AUTOSAR XML (schema 00050)
package /ComponentTypes
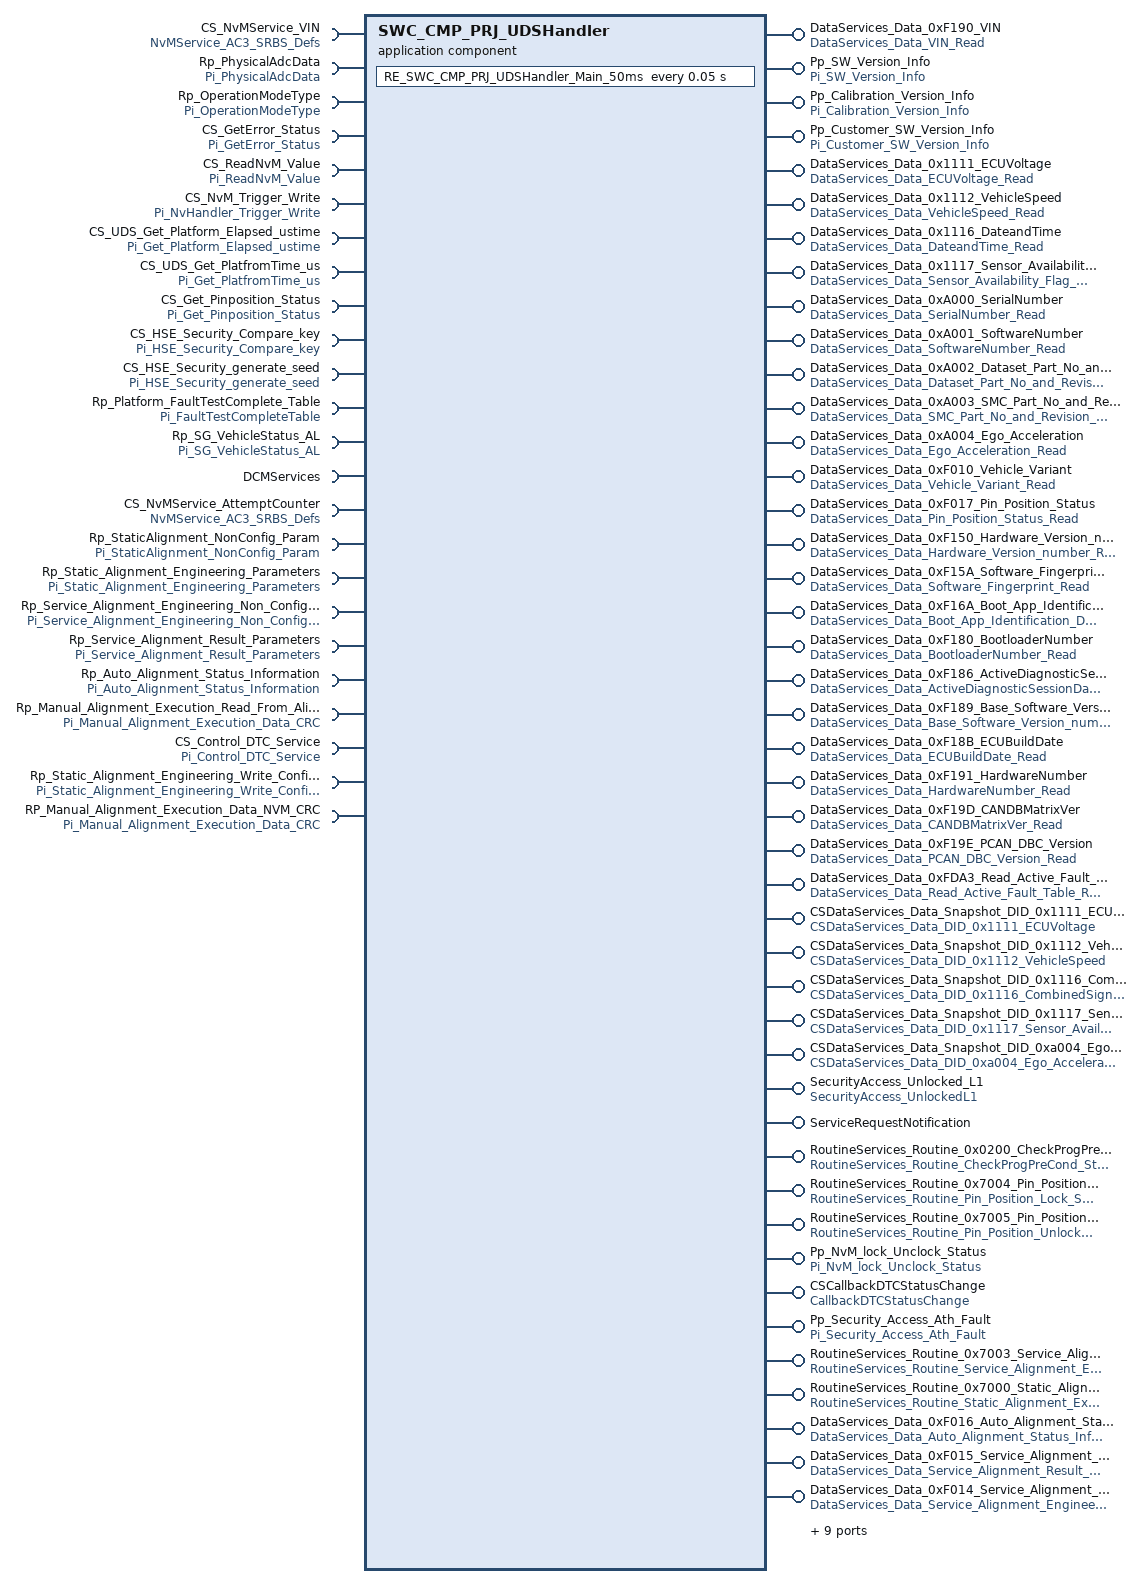
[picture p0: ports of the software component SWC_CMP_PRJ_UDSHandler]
  application sw component type SWC_CMP_PRJ_UDSHandler
    provide port DataServices_Data_0xF190_VIN: provided-interface=DataServices_Data_VIN_Read
      provided-com-specs:
        operation=WriteData, queue-length=1
        operation=ConditionCheckRead, queue-length=1
        operation=ReadData, queue-length=1
    require port CS_NvMService_VIN: required-com-specs=[EraseBlock, InvalidateNvBlock, RestoreBlockDefaults, WriteBlock, ReadBlock, SetRamBlockStatus, GetErrorStatus], required-interface=NvMService_AC3_SRBS_Defs
    25 x provide port:
      Pp_SW_Version_Info: nonqueued-sender-com-spec{data-element=De_SW_Version_Info, init-value=fields=[SwReleaseRevision:0, SwMajorRevision:0, SwMinorRevision:0, SwFieldRevision:0, DbcMajorRevision:0, DbcMinorRevision:0, FBLMajorRevision:0, FBLMinorRevision:0, FBLPromoteRevision:0, BMMajorRevision:0, BMMinorRevision:0, BMFieldRevision:0, ASRMajorRevision:0, ASRMinorRevision:0, ASRfieldRevision:0]}, provided-interface=Pi_SW_Version_Info
      Pp_Calibration_Version_Info: nonqueued-sender-com-spec{data-element=De_Calibration_Version_Info, init-value=fields=[SMC_MajorVersion:0, SMC_PlatformRevision:0, SMC_Compatablity:0, USC_MajorVersion:0, USC_PlatformRevision:0, USC_Compatablity:0, Julian_Year:0, Julian_Date:0]}, provided-interface=Pi_Calibration_Version_Info
      Pp_Customer_SW_Version_Info: nonqueued-sender-com-spec{data-element=De_Customer_SW_Version_Info, init-value=fields=[{short-label=Customer_SW_Version, fields=[Major_Version:0, Minor_Version:0, Patch_Version:0]}, {short-label=Customer_BL_Version, fields=[Major_Version:0, Minor_Version:0, Patch_Version:0]}, {short-label=Customer_BM_Version, fields=[Major_Version:0, Minor_Version:0, Patch_Version:0]}]}, provided-interface=Pi_Customer_SW_Version_Info
      DataServices_Data_0x1111_ECUVoltage: provided-com-specs=[{operation=ConditionCheckRead, queue-length=1}, {operation=ReadData, queue-length=1}], provided-interface=DataServices_Data_ECUVoltage_Read
      DataServices_Data_0x1112_VehicleSpeed: provided-com-specs=[{operation=ConditionCheckRead, queue-length=1}, {operation=ReadData, queue-length=1}], provided-interface=DataServices_Data_VehicleSpeed_Read
      DataServices_Data_0x1116_DateandTime: provided-com-specs=[{operation=ConditionCheckRead, queue-length=1}, {operation=ReadData, queue-length=1}], provided-interface=DataServices_Data_DateandTime_Read
      DataServices_Data_0x1117_Sensor_Availability_Flag: provided-com-specs=[{operation=ConditionCheckRead, queue-length=1}, {operation=ReadData, queue-length=1}], provided-interface=DataServices_Data_Sensor_Availability_Flag_Read
      DataServices_Data_0xA000_SerialNumber: provided-com-specs=[{operation=ConditionCheckRead, queue-length=1}, {operation=ReadData, queue-length=1}], provided-interface=DataServices_Data_SerialNumber_Read
      DataServices_Data_0xA001_SoftwareNumber: provided-com-specs=[{operation=ConditionCheckRead, queue-length=1}, {operation=ReadData, queue-length=1}], provided-interface=DataServices_Data_SoftwareNumber_Read
      DataServices_Data_0xA002_Dataset_Part_No_and_Revision: provided-com-specs=[{operation=ConditionCheckRead, queue-length=1}, {operation=ReadData, queue-length=1}], provided-interface=DataServices_Data_Dataset_Part_No_and_Revision_Read
      DataServices_Data_0xA003_SMC_Part_No_and_Revision: provided-com-specs=[{operation=ConditionCheckRead, queue-length=1}, {operation=ReadData, queue-length=1}], provided-interface=DataServices_Data_SMC_Part_No_and_Revision_Read
      DataServices_Data_0xA004_Ego_Acceleration: provided-com-specs=[{operation=ConditionCheckRead, queue-length=1}, {operation=ReadData, queue-length=1}], provided-interface=DataServices_Data_Ego_Acceleration_Read
      DataServices_Data_0xF010_Vehicle_Variant: provided-com-specs=[{operation=ConditionCheckRead, queue-length=1}, {operation=ReadData, queue-length=1}], provided-interface=DataServices_Data_Vehicle_Variant_Read
      DataServices_Data_0xF017_Pin_Position_Status: provided-com-specs=[{operation=ConditionCheckRead, queue-length=1}, {operation=ReadData, queue-length=1}], provided-interface=DataServices_Data_Pin_Position_Status_Read
      DataServices_Data_0xF150_Hardware_Version_number: provided-com-specs=[{operation=ConditionCheckRead, queue-length=1}, {operation=ReadData, queue-length=1}], provided-interface=DataServices_Data_Hardware_Version_number_Read
      DataServices_Data_0xF15A_Software_Fingerprint: provided-interface=DataServices_Data_Software_Fingerprint_Read
        provided-com-specs:
          operation=WriteData, queue-length=1
          operation=ConditionCheckRead, queue-length=1
          operation=ReadData, queue-length=1
      DataServices_Data_0xF16A_Boot_App_Identification: provided-com-specs=[{operation=ConditionCheckRead, queue-length=1}, {operation=ReadData, queue-length=1}], provided-interface=DataServices_Data_Boot_App_Identification_DID_Read
      DataServices_Data_0xF180_BootloaderNumber: provided-com-specs=[{operation=ConditionCheckRead, queue-length=1}, {operation=ReadData, queue-length=1}], provided-interface=DataServices_Data_BootloaderNumber_Read
      DataServices_Data_0xF186_ActiveDiagnosticSessionDataIdentifier: provided-com-specs=[{operation=ConditionCheckRead, queue-length=1}, {operation=ReadData, queue-length=1}], provided-interface=DataServices_Data_ActiveDiagnosticSessionDataIdentifier_Read
      DataServices_Data_0xF189_Base_Software_Version_number: provided-com-specs=[{operation=ConditionCheckRead, queue-length=1}, {operation=ReadData, queue-length=1}], provided-interface=DataServices_Data_Base_Software_Version_number_Read
      DataServices_Data_0xF18B_ECUBuildDate: provided-com-specs=[{operation=ConditionCheckRead, queue-length=1}, {operation=ReadData, queue-length=1}], provided-interface=DataServices_Data_ECUBuildDate_Read
      DataServices_Data_0xF191_HardwareNumber: provided-com-specs=[{operation=ConditionCheckRead, queue-length=1}, {operation=ReadData, queue-length=1}], provided-interface=DataServices_Data_HardwareNumber_Read
      DataServices_Data_0xF19D_CANDBMatrixVer: provided-com-specs=[{operation=ConditionCheckRead, queue-length=1}, {operation=ReadData, queue-length=1}], provided-interface=DataServices_Data_CANDBMatrixVer_Read
      DataServices_Data_0xF19E_PCAN_DBC_Version: provided-com-specs=[{operation=ConditionCheckRead, queue-length=1}, {operation=ReadData, queue-length=1}], provided-interface=DataServices_Data_PCAN_DBC_Version_Read
      DataServices_Data_0xFDA3_Read_Active_Fault_Table: provided-com-specs=[{operation=ConditionCheckRead, queue-length=1}, {operation=ReadData, queue-length=1}], provided-interface=DataServices_Data_Read_Active_Fault_Table_Read
    require port Rp_PhysicalAdcData: nonqueued-receiver-com-spec{data-element=De_PhysicalAdcData, filter=data-filter-type=ALWAYS, init-value=fields=[Adc_Board_Rev:0, Adc_Batt_Volt:0, Adc_Pos_Gnd_A:0, Adc_Pos_Gnd_B:0, Adc_Pos_Gnd_C:0, Adc_Pos_Gnd_D:0, Adc_Eth_0v9:0, Adc_Rdi_Detect:0, Adc_MMIC_Temp:0, Adc_Mcu_Temp:0, Validity_Flag:0]}, required-interface=Pi_PhysicalAdcData
    require port Rp_OperationModeType: nonqueued-receiver-com-spec{data-element=De_OperationMode_System, filter=data-filter-type=ALWAYS, init-value=0}, required-interface=Pi_OperationModeType
    10 x provide port:
      CSDataServices_Data_Snapshot_DID_0x1111_ECUVoltage: server-com-spec{operation=ReadData, queue-length=1}, provided-interface=CSDataServices_Data_DID_0x1111_ECUVoltage
      CSDataServices_Data_Snapshot_DID_0x1112_VehicleSpeed: server-com-spec{operation=ReadData, queue-length=1}, provided-interface=CSDataServices_Data_DID_0x1112_VehicleSpeed
      CSDataServices_Data_Snapshot_DID_0x1116_CombinedSignal: server-com-spec{operation=ReadData, queue-length=1}, provided-interface=CSDataServices_Data_DID_0x1116_CombinedSignal
      CSDataServices_Data_Snapshot_DID_0x1117_Sensor_Availability_Flag_Information: server-com-spec{operation=ReadData, queue-length=1}, provided-interface=CSDataServices_Data_DID_0x1117_Sensor_Availability_Flag_Information
      CSDataServices_Data_Snapshot_DID_0xa004_Ego_Acceleration: server-com-spec{operation=ReadData, queue-length=1}, provided-interface=CSDataServices_Data_DID_0xa004_Ego_Acceleration
      SecurityAccess_Unlocked_L1: provided-interface=SecurityAccess_UnlockedL1
        provided-com-specs:
          operation=CompareKey, queue-length=1
          operation=GetSeed, queue-length=1
          operation=SetSecurityAttemptCounter, queue-length=1
          operation=GetSecurityAttemptCounter, queue-length=1
      ServiceRequestNotification: provided-com-specs=[{operation=Confirmation, queue-length=1}, {operation=Indication, queue-length=1}], provided-interface=ServiceRequestNotification
      RoutineServices_Routine_0x0200_CheckProgPreCond_Start: server-com-spec{operation=Start, queue-length=1}, provided-interface=RoutineServices_Routine_CheckProgPreCond_Start
      RoutineServices_Routine_0x7004_Pin_Position_Lock_Start: provided-com-specs=[{operation=RequestResults, queue-length=1}, {operation=Start, queue-length=1}], provided-interface=RoutineServices_Routine_Pin_Position_Lock_Start
      RoutineServices_Routine_0x7005_Pin_Position_Unlock_Start: provided-com-specs=[{operation=RequestResults, queue-length=1}, {operation=Start, queue-length=1}], provided-interface=RoutineServices_Routine_Pin_Position_Unlock_Start
    require port CS_GetError_Status: client-com-spec=Operation, required-interface=Pi_GetError_Status
    require port CS_ReadNvM_Value: client-com-spec=Operation, required-interface=Pi_ReadNvM_Value
    require port CS_NvM_Trigger_Write: client-com-spec=NvHandler_Trigger_Write_To_NVM, required-interface=Pi_NvHandler_Trigger_Write
    provide port Pp_NvM_lock_Unclock_Status: nonqueued-sender-com-spec{data-element=De_NvM_lock_Unclock_Status, init-value=constant-reference=C_SensorPos_default}, provided-interface=Pi_NvM_lock_Unclock_Status
    provide port CSCallbackDTCStatusChange: server-com-spec{operation=DTCStatusChanged, queue-length=1}, provided-interface=CallbackDTCStatusChange
    provide port Pp_Security_Access_Ath_Fault: nonqueued-sender-com-spec{data-element=De_Security_Access_Ath_Fault, init-value=170}, provided-interface=Pi_Security_Access_Ath_Fault
    8 x require port:
      CS_UDS_Get_Platform_Elapsed_ustime: client-com-spec=read, required-interface=Pi_Get_Platform_Elapsed_ustime
      CS_UDS_Get_PlatfromTime_us: client-com-spec=read, required-interface=Pi_Get_PlatfromTime_us
      CS_Get_Pinposition_Status: client-com-spec=Operation, required-interface=Pi_Get_Pinposition_Status
      CS_HSE_Security_Compare_key: client-com-spec=Operation, required-interface=Pi_HSE_Security_Compare_key
      CS_HSE_Security_generate_seed: client-com-spec=Operation, required-interface=Pi_HSE_Security_generate_seed
      Rp_Platform_FaultTestComplete_Table: nonqueued-receiver-com-spec{data-element=De_FaultTestCompleteTable, filter=data-filter-type=ALWAYS, init-value=constant-reference=C_Fault_T}, required-interface=Pi_FaultTestCompleteTable
      Rp_SG_VehicleStatus_AL: nonqueued-receiver-com-spec{data-element=Vdp_SG_VehicleStatus_AL, filter=data-filter-type=ALWAYS, init-value=fields=[SSTS_CAN_PCAN_MAJOR_ADAS:0, SSTS_CAN_PCAN_MINOR_ADAS:0, SSTS_DRIVE_DIR:0, SSTS_DRIVE_REVERSE:0, SSTS_GEAR_POSITION:0, SSTS_IGN_STATUS:0, SSTS_MH_VS_CRC16:0, SSTS_MH_VS_CYCLE_COUNTER:0, SSTS_STEERING_ANGLE:0, SSTS_STEERING_ANGLE_SIGN:0, SSTS_SW_VERSION_ADAS:0, SSTS_VEH_AbsoluteTime_Day:0, SSTS_VEH_AbsoluteTime_Hour:0, SSTS_VEH_AbsoluteTime_Minute:0, SSTS_VEH_AbsoluteTime_Month:0, SSTS_VEH_AbsoluteTime_Second:0, SSTS_VEH_AbsoluteTime_Year:0, SSTS_VEH_ODOMETER:0, SSTS_VEH_POWER_MODE_STATUS:0, SSTS_VEH_SPD_COMP_FACTOR:0, SSTS_VEH_Status_CMAC:5 x 0, SSTS_VEH_Status_FV:7 x 0, SSTS_VEH_SYSTEM_VOLTAGE:0, SSTS_VEH_TRAILER_CONNECTED:0, SSTS_VEH_VARIANT:0, SSTS_VEHICLE_SPEED_CALC:0, SSTS_VEHICLE_SPEED_CALC_QF:0, SSTS_VEHICLE_STATE:0, SSTS_VIN_Data_Byte0:0, SSTS_VIN_Data_Byte1:0, SSTS_VIN_Data_Byte2:0, SSTS_VIN_Data_Byte3:0, SSTS_VIN_Data_Byte4:0, SSTS_VIN_Data_Byte5:0, SSTS_VIN_Data_Byte6:0, SSTS_VIN_FrameIdx:0, SSTS_YAW_RATE_BIAS:0, SSTS_YAW_RATE_CALC:0, SSTS_YAW_RATE_CALC_QF:0]}, required-interface=Pi_SG_VehicleStatus_AL
      DCMServices: required-interface=DCMServices
        required-com-specs:
          GetRequestKind
          SetActiveDiagnostic
          GetSecurityLevel
          ResetToDefaultSession
          GetSesCtrlType
          GetActiveProtocol
    10 x provide port:
      RoutineServices_Routine_0x7003_Service_Alignment_Execution_Start: provided-interface=RoutineServices_Routine_Service_Alignment_Execution_Start
        provided-com-specs:
          operation=RequestResults, queue-length=1
          operation=Stop, queue-length=1
          operation=Start, queue-length=1
      RoutineServices_Routine_0x7000_Static_Alignment_Execution_Start: provided-interface=RoutineServices_Routine_Static_Alignment_Execution_Start
        provided-com-specs:
          operation=RequestResults, queue-length=1
          operation=Stop, queue-length=1
          operation=Start, queue-length=1
      DataServices_Data_0xF016_Auto_Alignment_Status_Information: provided-com-specs=[{operation=ConditionCheckRead, queue-length=1}, {operation=ReadData, queue-length=1}], provided-interface=DataServices_Data_Auto_Alignment_Status_Information_Read
      DataServices_Data_0xF015_Service_Alignment_Result_Parameters: provided-com-specs=[{operation=ConditionCheckRead, queue-length=1}, {operation=ReadData, queue-length=1}], provided-interface=DataServices_Data_Service_Alignment_Result_Parameters_Read
      DataServices_Data_0xF014_Service_Alignment_Engineering_Non_Configuration_Parameters: provided-com-specs=[{operation=ConditionCheckRead, queue-length=1}, {operation=ReadData, queue-length=1}], provided-interface=DataServices_Data_Service_Alignment_Engineering_Non_Configuration_Parameters_Read
      DataServices_Data_0xF013_Static_Alignment_Engineering_Write_Configuration_Parameter: server-com-spec{operation=WriteData, queue-length=1}, provided-interface=DataServices_Data_Static_Alignment_Engineering_Write_Configuration_Parameter_Write
      DataServices_Data_0xF012_Static_Alignment_Engineering_Read_Parameters: provided-com-specs=[{operation=ConditionCheckRead, queue-length=1}, {operation=ReadData, queue-length=1}], provided-interface=DataServices_Data_Static_Alignment_Engineering_Read_Parameters_Read
      DataServices_Data_0xF011_Static_Alignment_Engineering_Non_Configuration_Parameters: provided-com-specs=[{operation=ConditionCheckRead, queue-length=1}, {operation=ReadData, queue-length=1}], provided-interface=DataServices_Data_Static_Alignment_Engineering_Non_Configuration_Parameters_Read
      DataServices_Data_0xF01C_Static_Alignment_Result_Parameters: provided-com-specs=[{operation=ConditionCheckRead, queue-length=1}, {operation=ReadData, queue-length=1}], provided-interface=DataServices_Data_Static_Alignment_Result_Parameters_Read
      DataServices_Data_0xF01B_Manual_Alignment_Execution: provided-interface=DataServices_Data_Manual_Alignment_Execution_Read
        provided-com-specs:
          operation=WriteData, queue-length=1
          operation=ConditionCheckRead, queue-length=1
          operation=ReadData, queue-length=1
    require port CS_NvMService_AttemptCounter: required-com-specs=[WriteBlock, SetRamBlockStatus, RestoreBlockDefaults, ReadBlock, InvalidateNvBlock, GetErrorStatus, EraseBlock], required-interface=NvMService_AC3_SRBS_Defs
    require port Rp_StaticAlignment_NonConfig_Param: nonqueued-receiver-com-spec{data-element=De_DID_StaticAlignment_NonConfig_Param_T, filter=data-filter-type=ALWAYS, init-value=fields=[AlignmentStatic_NumberOfScans:0, AlignmentStatic_RangeOffset_Threshold:0, RangeRateUpper_Threshold:0, RCS_Min:0, RCS_Max:0, Velocity_Max:0, Yaw_Max:0, FlatPlateWidth_Lower_Limit:0, FlatPlateWidth_Upper_Limit:0, FlatPlateHeight_Lower_Limit:0, FlatPlateHeight_Upper_Limit:0, FlatPlateRCS_Lower_Limit:0, FlatPlateRCS_Upper_Limit:0, FlatPlateRange_Lower_Limit:0, FlatPlateRange_Upper_Limit:0, FlatPlateAzimuth_Lower_Limit:0, FlatPlateAzimuth_Upper_Limit:0, FlatPlateElevation_Lower_Limit:0, FlatPlateElevation_Upper_Limit:0, FlatPlateRangeRate_Lower_Limit:0, FlatPlateRangeRate_Upper_Limit:0]}, required-interface=Pi_StaticAlignment_NonConfig_Param
    require port Rp_Static_Alignment_Engineering_Parameters: nonqueued-receiver-com-spec{data-element=De_Static_Alignment_Engineering_Parameters, filter=data-filter-type=ALWAYS, init-value=fields=[AlignmentStatic_AzimuthUpper_Threshold:0, AlignmentStatic_AzimuthLower_Threshold:0, AlignmentStatic_ElevationUpper_Threshold:0, AlignmentStatic_ElevationLower_Threshold:0, AlignmentStatic_TargetAzimuth:0, AlignmentStatic_TargetElevation:0, AlignmentStatic_TargetDistance:0]}, required-interface=Pi_Static_Alignment_Engineering_Parameters
    provide port Pp_Static_Alignment_Engineering_Write_Configuration_Parameters_CRC: nonqueued-sender-com-spec{data-element=De_Static_Alignment_Engineering_Write_Configuration_Parameters_CRC, init-value=fields=[{short-label=Static_alignment_write_Params, fields=[AlignmentStatic_TargetAzimuth:0, AlignmentStatic_TargetElevation:0, AlignmentStatic_TargetDistance:120]}, Data_CRC:0]}, provided-interface=Pi_Static_Alignment_Engineering_Write_Configuration_Parameters_CRC
    4 x require port:
      Rp_Service_Alignment_Engineering_Non_Configuration_Parameters: nonqueued-receiver-com-spec{data-element=De_Service_Alignment_Engineering_Non_Configuration_Parameters, filter=data-filter-type=ALWAYS, init-value=fields=[AlignService_Abs_Dist_Th:0, AlignService_Eff_Dist_Th:0, AlignService_Abs_Duration_Th:0, AlignService_Eff_Duration_Th:0, AlignService_Vel_Min:0, AlignService_Vel_Max:0, AlignService_Yawrate_Max:0]}, required-interface=Pi_Service_Alignment_Engineering_Non_Configuration_Parameters
      Rp_Service_Alignment_Result_Parameters: nonqueued-receiver-com-spec{data-element=De_Service_Alignment_Result_Parameters, filter=data-filter-type=ALWAYS, init-value=fields=[AlignmentModeOut:0, AlignmentServiceStatus:0, AlignmentError:0, AlignmentAzimuth:0, AlignmentElevation:0, AlignmentRoll:0, AzimuthStd:0, ElevationStd:0, RollStd:0, CalTime:0, ProgressPercent:0, CalDisplay:0, 0, 0, 0, 0, VehicleCondition:0, AverageNumberOfDetections:0, AverageSpeed:0, DistanceAbsolute:0, DistanceEffective:0, DurationAbsolute:0, DurationEffective:0, 0, 0, 0, 0]}, required-interface=Pi_Service_Alignment_Result_Parameters
      Rp_Auto_Alignment_Status_Information: nonqueued-receiver-com-spec{data-element=De_Auto_Alignment_Status_Information, filter=data-filter-type=ALWAYS, init-value=fields=[AlignmentModeOut:0, AlignmentAutoStatus:0, AutoAlignmentFailRootCause:0, StartAzimuth:0, StartElevation:0, StartRoll:0, AACurrentAzimuth:0, AACurrentElevation:0, AACurrentRoll:0, AAAzimuthStd:0, AAElevationStd:0, AARollStd:0, 0, 0, 0, 0, AzimuthError_positive:0, ElevationError_positive:0, RollError_positive:0, AzimuthError_negative:0, ElevationError_negative:0, RollError_negative:0, HostSpeedCompensationFactor:0, HostSpeedCompensationFactor_QF:0, AzimuthUpdates:0, ElevationUpdates:0, RollUpdates:0]}, required-interface=Pi_Auto_Alignment_Status_Information
      Rp_Manual_Alignment_Execution_Read_From_Alignment_Data_CRC: nonqueued-receiver-com-spec{data-element=De_Manual_Alignment_Execution_Data_CRC, filter=data-filter-type=ALWAYS, init-value=fields=[{short-label=Manual_Alignment_Execution_Data, fields=[AlignmentModeIn:0, 0, IntialMisalignmentAngleAzimuth:0, IntialMisalignmentAngleElevation:0]}, Data_CRC:0]}, required-interface=Pi_Manual_Alignment_Execution_Data_CRC
    provide port Pp_Manual_Alignment_Execution_Data_From_UDS_CRC: nonqueued-sender-com-spec{data-element=De_Manual_Alignment_Execution_Data_CRC, init-value=fields=[{short-label=Manual_Alignment_Execution_Data, fields=[AlignmentModeIn:0, 0, IntialMisalignmentAngleAzimuth:0, IntialMisalignmentAngleElevation:0]}, Data_CRC:0]}, provided-interface=Pi_Manual_Alignment_Execution_Data_CRC
    require port CS_Control_DTC_Service: client-com-spec=Operation, required-interface=Pi_Control_DTC_Service
    provide port Pp_Static_Alignment_Engineering_Write_Configuration_Parameters_NVM_CRC: nonqueued-sender-com-spec{data-element=De_Static_Alignment_Engineering_Write_Configuration_Parameters_CRC, init-value=fields=[{short-label=Static_alignment_write_Params, fields=[AlignmentStatic_TargetAzimuth:0, AlignmentStatic_TargetElevation:0, AlignmentStatic_TargetDistance:0]}, Data_CRC:0]}, provided-interface=Pi_Static_Alignment_Engineering_Write_Configuration_Parameters_CRC
    require port Rp_Static_Alignment_Engineering_Write_Configuration_Parameters_NVM_CRC: nonqueued-receiver-com-spec{data-element=De_Static_Alignment_Engineering_Write_Configuration_Parameters_CRC, filter=data-filter-type=ALWAYS, init-value=fields=[{short-label=Static_alignment_write_Params, fields=[AlignmentStatic_TargetAzimuth:0, AlignmentStatic_TargetElevation:0, AlignmentStatic_TargetDistance:0]}, Data_CRC:0]}, required-interface=Pi_Static_Alignment_Engineering_Write_Configuration_Parameters_CRC
    provide port Pp_Manual_Alignment_Execution_Data_NVM_CRC: nonqueued-sender-com-spec{data-element=De_Manual_Alignment_Execution_Data_CRC, init-value=fields=[{short-label=Manual_Alignment_Execution_Data, fields=[AlignmentModeIn:0, 0, IntialMisalignmentAngleAzimuth:0, IntialMisalignmentAngleElevation:0]}, Data_CRC:0]}, provided-interface=Pi_Manual_Alignment_Execution_Data_CRC
    require port RP_Manual_Alignment_Execution_Data_NVM_CRC: nonqueued-receiver-com-spec{data-element=De_Manual_Alignment_Execution_Data_CRC, filter=data-filter-type=ALWAYS, init-value=fields=[{short-label=Manual_Alignment_Execution_Data, fields=[AlignmentModeIn:0, 0, IntialMisalignmentAngleAzimuth:0, IntialMisalignmentAngleElevation:0]}, Data_CRC:0]}, required-interface=Pi_Manual_Alignment_Execution_Data_CRC
    behavior SWC_CMP_PRJ_UDSHandler_InternalBehavior: data-type-mapping=[DataTypeMappings_DEV, defaultDataTypeMappingSet_CPFS], handle-termination-and-restart=NO-SUPPORT
      ar-typed-per-instance-memorys:
        data SWC_UDS_VIN: sw-calibration-access=READ-ONLY, type=Dt_VIN_T, init-value=constant-reference=C_VIN_T
        data SWC_UDS_AttemptCounter: sw-calibration-access=READ-ONLY, type=AttempCounter_Type, init-value=fields=[AttemptCounter1:0, AttemptCounter2:0]
      operation invoked event OIT_DataServices_Data_0xF190_VIN_WriteData_DataServices_Data_0xF190_VIN_WriteData: start-on-event=DataServices_Data_0xF190_VIN_WriteData, operation=DataServices_Data_0xF190_VIN.WriteData
      operation invoked event OIT_DataServices_Data_0xF190_VIN_ConditionCheckRead_DataServices_Data_0xF190_VIN_ConditionCheckRead: start-on-event=DataServices_Data_0xF190_VIN_ConditionCheckRead, operation=DataServices_Data_0xF190_VIN.ConditionCheckRead
      operation invoked event OIT_DataServices_Data_0xF190_VIN_ReadData_DataServices_Data_0xF190_VIN_ReadData: start-on-event=DataServices_Data_0xF190_VIN_ReadData, operation=DataServices_Data_0xF190_VIN.ReadData
      timing event TMT_RE_SWC_CMP_PRJ_UDSHandler_Main_50ms: start-on-event=RE_SWC_CMP_PRJ_UDSHandler_Main_50ms, period=0.05
      84 x operation invoked event:
        OIT_DataServices_Data_0x1111_ECUVoltage_ConditionCheckRead_DataServices_Data_0x1111_ECUVoltage_ConditionCheckRead: start-on-event=DataServices_Data_0x1111_ECUVoltage_ConditionCheckRead, operation=DataServices_Data_0x1111_ECUVoltage.ConditionCheckRead
        OIT_DataServices_Data_0x1111_ECUVoltage_ReadData_DataServices_Data_0x1111_ECUVoltage_ReadData: start-on-event=DataServices_Data_0x1111_ECUVoltage_ReadData, operation=DataServices_Data_0x1111_ECUVoltage.ReadData
        OIT_DataServices_Data_0x1112_VehicleSpeed_ConditionCheckRead_DataServices_Data_0x1112_VehicleSpeed_ConditionCheckRead: start-on-event=DataServices_Data_0x1112_VehicleSpeed_ConditionCheckRead, operation=DataServices_Data_0x1112_VehicleSpeed.ConditionCheckRead
        OIT_DataServices_Data_0x1112_VehicleSpeed_ReadData_DataServices_Data_0x1112_VehicleSpeed_ReadData: start-on-event=DataServices_Data_0x1112_VehicleSpeed_ReadData, operation=DataServices_Data_0x1112_VehicleSpeed.ReadData
        OIT_DataServices_Data_0x1116_DateandTime_ConditionCheckRead_DataServices_Data_0x1116_DateandTime_ConditionCheckRead: start-on-event=DataServices_Data_0x1116_DateandTime_ConditionCheckRead, operation=DataServices_Data_0x1116_DateandTime.ConditionCheckRead
        OIT_DataServices_Data_0x1116_DateandTime_ReadData_DataServices_Data_0x1116_DateandTime_ReadData: start-on-event=DataServices_Data_0x1116_DateandTime_ReadData, operation=DataServices_Data_0x1116_DateandTime.ReadData
        OIT_DataServices_Data_0x1117_Sensor_Availability_Flag_ConditionCheckRead_DataServices_Data_0x1117_Sensor_Availability_FlC3AC68A5: start-on-event=DataServices_Data_0x1117_Sensor_Availability_Flag_ConditionCheckRead, operation=DataServices_Data_0x1117_Sensor_Availability_Flag.ConditionCheckRead
        OIT_DataServices_Data_0x1117_Sensor_Availability_Flag_ReadData_DataServices_Data_0x1117_Sensor_Availability_Flag_ReadData: start-on-event=DataServices_Data_0x1117_Sensor_Availability_Flag_ReadData, operation=DataServices_Data_0x1117_Sensor_Availability_Flag.ReadData
        OIT_DataServices_Data_0xA000_SerialNumber_ConditionCheckRead_DataServices_Data_0xA000_SerialNumber_ConditionCheckRead: start-on-event=DataServices_Data_0xA000_SerialNumber_ConditionCheckRead, operation=DataServices_Data_0xA000_SerialNumber.ConditionCheckRead
        OIT_DataServices_Data_0xA000_SerialNumber_ReadData_DataServices_Data_0xA000_SerialNumber_ReadData: start-on-event=DataServices_Data_0xA000_SerialNumber_ReadData, operation=DataServices_Data_0xA000_SerialNumber.ReadData
        OIT_DataServices_Data_0xA001_SoftwareNumber_ConditionCheckRead_DataServices_Data_0xA001_SoftwareNumber_ConditionCheckRead: start-on-event=DataServices_Data_0xA001_SoftwareNumber_ConditionCheckRead, operation=DataServices_Data_0xA001_SoftwareNumber.ConditionCheckRead
        OIT_DataServices_Data_0xA001_SoftwareNumber_ReadData_DataServices_Data_0xA001_SoftwareNumber_ReadData: start-on-event=DataServices_Data_0xA001_SoftwareNumber_ReadData, operation=DataServices_Data_0xA001_SoftwareNumber.ReadData
        OIT_DataServices_Data_0xA002_Dataset_Part_No_and_Revision_ConditionCheckRead_DataServices_Data_0xA002_Dataset_Part_No_an2C00C244: start-on-event=DataServices_Data_0xA002_Dataset_Part_No_and_Revision_ConditionCheckRead, operation=DataServices_Data_0xA002_Dataset_Part_No_and_Revision.ConditionCheckRead
        OIT_DataServices_Data_0xA002_Dataset_Part_No_and_Revision_ReadData_DataServices_Data_0xA002_Dataset_Part_No_and_Revision58D1EF9A: start-on-event=DataServices_Data_0xA002_Dataset_Part_No_and_Revision_ReadData, operation=DataServices_Data_0xA002_Dataset_Part_No_and_Revision.ReadData
        OIT_DataServices_Data_0xA003_SMC_Part_No_and_Revision_ConditionCheckRead_DataServices_Data_0xA003_SMC_Part_No_and_Revisi4479C802: start-on-event=DataServices_Data_0xA003_SMC_Part_No_and_Revision_ConditionCheckRead, operation=DataServices_Data_0xA003_SMC_Part_No_and_Revision.ConditionCheckRead
        OIT_DataServices_Data_0xA003_SMC_Part_No_and_Revision_ReadData_DataServices_Data_0xA003_SMC_Part_No_and_Revision_ReadData: start-on-event=DataServices_Data_0xA003_SMC_Part_No_and_Revision_ReadData, operation=DataServices_Data_0xA003_SMC_Part_No_and_Revision.ReadData
        OIT_DataServices_Data_0xA004_Ego_Acceleration_ConditionCheckRead_DataServices_Data_0xA004_Ego_Acceleration_ConditionCheckRead: start-on-event=DataServices_Data_0xA004_Ego_Acceleration_ConditionCheckRead, operation=DataServices_Data_0xA004_Ego_Acceleration.ConditionCheckRead
        OIT_DataServices_Data_0xA004_Ego_Acceleration_ReadData_DataServices_Data_0xA004_Ego_Acceleration_ReadData: start-on-event=DataServices_Data_0xA004_Ego_Acceleration_ReadData, operation=DataServices_Data_0xA004_Ego_Acceleration.ReadData
        OIT_DataServices_Data_0xF010_Vehicle_Variant_ConditionCheckRead_DataServices_Data_0xF010_Vehicle_Variant_ConditionCheckRead: start-on-event=DataServices_Data_0xF010_Vehicle_Variant_ConditionCheckRead, operation=DataServices_Data_0xF010_Vehicle_Variant.ConditionCheckRead
        OIT_DataServices_Data_0xF010_Vehicle_Variant_ReadData_DataServices_Data_0xF010_Vehicle_Variant_ReadData: start-on-event=DataServices_Data_0xF010_Vehicle_Variant_ReadData, operation=DataServices_Data_0xF010_Vehicle_Variant.ReadData
        OIT_DataServices_Data_0xF017_Pin_Position_Status_ConditionCheckRead_DataServices_Data_0xF017_Pin_Position_Status_Conditi46601389: start-on-event=DataServices_Data_0xF017_Pin_Position_Status_ConditionCheckRead, operation=DataServices_Data_0xF017_Pin_Position_Status.ConditionCheckRead
        OIT_DataServices_Data_0xF017_Pin_Position_Status_ReadData_DataServices_Data_0xF017_Pin_Position_Status_ReadData: start-on-event=DataServices_Data_0xF017_Pin_Position_Status_ReadData, operation=DataServices_Data_0xF017_Pin_Position_Status.ReadData
        OIT_DataServices_Data_0xF150_Hardware_Version_number_ConditionCheckRead_DataServices_Data_0xF150_Hardware_Version_number5319F0E0: start-on-event=DataServices_Data_0xF150_Hardware_Version_number_ConditionCheckRead, operation=DataServices_Data_0xF150_Hardware_Version_number.ConditionCheckRead
        OIT_DataServices_Data_0xF150_Hardware_Version_number_ReadData_DataServices_Data_0xF150_Hardware_Version_number_ReadData: start-on-event=DataServices_Data_0xF150_Hardware_Version_number_ReadData, operation=DataServices_Data_0xF150_Hardware_Version_number.ReadData
        OIT_DataServices_Data_0xF15A_Software_Fingerprint_WriteData_DataServices_Data_0xF15A_Software_Fingerprint_WriteData: start-on-event=DataServices_Data_0xF15A_Software_Fingerprint_WriteData, operation=DataServices_Data_0xF15A_Software_Fingerprint.WriteData
        OIT_DataServices_Data_0xF15A_Software_Fingerprint_ConditionCheckRead_DataServices_Data_0xF15A_Software_Fingerprint_Condi6D559378: start-on-event=DataServices_Data_0xF15A_Software_Fingerprint_ConditionCheckRead, operation=DataServices_Data_0xF15A_Software_Fingerprint.ConditionCheckRead
        OIT_DataServices_Data_0xF15A_Software_Fingerprint_ReadData_DataServices_Data_0xF15A_Software_Fingerprint_ReadData: start-on-event=DataServices_Data_0xF15A_Software_Fingerprint_ReadData, operation=DataServices_Data_0xF15A_Software_Fingerprint.ReadData
        OIT_DataServices_Data_0xF16A_Boot_App_Identification_ConditionCheckRead_DataServices_Data_0xF16A_Boot_App_Identification9C41B615: start-on-event=DataServices_Data_0xF16A_Boot_App_Identification_ConditionCheckRead, operation=DataServices_Data_0xF16A_Boot_App_Identification.ConditionCheckRead
        OIT_DataServices_Data_0xF16A_Boot_App_Identification_ReadData_DataServices_Data_0xF16A_Boot_App_Identification_ReadData: start-on-event=DataServices_Data_0xF16A_Boot_App_Identification_ReadData, operation=DataServices_Data_0xF16A_Boot_App_Identification.ReadData
        OIT_DataServices_Data_0xF180_BootloaderNumber_ConditionCheckRead_DataServices_Data_0xF180_BootloaderNumber_ConditionCheckRead: start-on-event=DataServices_Data_0xF180_BootloaderNumber_ConditionCheckRead, operation=DataServices_Data_0xF180_BootloaderNumber.ConditionCheckRead
        OIT_DataServices_Data_0xF180_BootloaderNumber_ReadData_DataServices_Data_0xF180_BootloaderNumber_ReadData: start-on-event=DataServices_Data_0xF180_BootloaderNumber_ReadData, operation=DataServices_Data_0xF180_BootloaderNumber.ReadData
        OIT_DataServices_Data_0xF186_ActiveDiagnosticSessionDataIdentifier_ConditionCheckRead_DataServices_Data_0xF186_ActiveDia76F3A2B5: start-on-event=DataServices_Data_0xF186_ActiveDiagnosticSessionDataIdentifier_ConditionCheckRead, operation=DataServices_Data_0xF186_ActiveDiagnosticSessionDataIdentifier.ConditionCheckRead
        OIT_DataServices_Data_0xF186_ActiveDiagnosticSessionDataIdentifier_ReadData_DataServices_Data_0xF186_ActiveDiagnosticSes4023728F: start-on-event=DataServices_Data_0xF186_ActiveDiagnosticSessionDataIdentifier_ReadData, operation=DataServices_Data_0xF186_ActiveDiagnosticSessionDataIdentifier.ReadData
        OIT_DataServices_Data_0xF189_Base_Software_Version_number_ConditionCheckRead_DataServices_Data_0xF189_Base_Software_Vers7E0CB6E2: start-on-event=DataServices_Data_0xF189_Base_Software_Version_number_ConditionCheckRead, operation=DataServices_Data_0xF189_Base_Software_Version_number.ConditionCheckRead
        OIT_DataServices_Data_0xF189_Base_Software_Version_number_ReadData_DataServices_Data_0xF189_Base_Software_Version_number3E358C8D: start-on-event=DataServices_Data_0xF189_Base_Software_Version_number_ReadData, operation=DataServices_Data_0xF189_Base_Software_Version_number.ReadData
        OIT_DataServices_Data_0xF18B_ECUBuildDate_ConditionCheckRead_DataServices_Data_0xF18B_ECUBuildDate_ConditionCheckRead: start-on-event=DataServices_Data_0xF18B_ECUBuildDate_ConditionCheckRead, operation=DataServices_Data_0xF18B_ECUBuildDate.ConditionCheckRead
        OIT_DataServices_Data_0xF18B_ECUBuildDate_ReadData_DataServices_Data_0xF18B_ECUBuildDate_ReadData: start-on-event=DataServices_Data_0xF18B_ECUBuildDate_ReadData, operation=DataServices_Data_0xF18B_ECUBuildDate.ReadData
        OIT_DataServices_Data_0xF191_HardwareNumber_ConditionCheckRead_DataServices_Data_0xF191_HardwareNumber_ConditionCheckRead: start-on-event=DataServices_Data_0xF191_HardwareNumber_ConditionCheckRead, operation=DataServices_Data_0xF191_HardwareNumber.ConditionCheckRead
        OIT_DataServices_Data_0xF191_HardwareNumber_ReadData_DataServices_Data_0xF191_HardwareNumber_ReadData: start-on-event=DataServices_Data_0xF191_HardwareNumber_ReadData, operation=DataServices_Data_0xF191_HardwareNumber.ReadData
        OIT_DataServices_Data_0xF19D_CANDBMatrixVer_ConditionCheckRead_DataServices_Data_0xF19D_CANDBMatrixVer_ConditionCheckRead: start-on-event=DataServices_Data_0xF19D_CANDBMatrixVer_ConditionCheckRead, operation=DataServices_Data_0xF19D_CANDBMatrixVer.ConditionCheckRead
        OIT_DataServices_Data_0xF19D_CANDBMatrixVer_ReadData_DataServices_Data_0xF19D_CANDBMatrixVer_ReadData: start-on-event=DataServices_Data_0xF19D_CANDBMatrixVer_ReadData, operation=DataServices_Data_0xF19D_CANDBMatrixVer.ReadData
        OIT_DataServices_Data_0xF19E_PCAN_DBC_Version_ConditionCheckRead_DataServices_Data_0xF19E_PCAN_DBC_Version_ConditionCheckRead: start-on-event=DataServices_Data_0xF19E_PCAN_DBC_Version_ConditionCheckRead, operation=DataServices_Data_0xF19E_PCAN_DBC_Version.ConditionCheckRead
        OIT_DataServices_Data_0xF19E_PCAN_DBC_Version_ReadData_DataServices_Data_0xF19E_PCAN_DBC_Version_ReadData: start-on-event=DataServices_Data_0xF19E_PCAN_DBC_Version_ReadData, operation=DataServices_Data_0xF19E_PCAN_DBC_Version.ReadData
        OIT_CSDataServices_Data_Snapshot_DID_0x1111_ECUVoltage_ReadData_CSDataServices_Data_Snapshot_DID_0x1111_ECUVoltage_ReadData: start-on-event=CSDataServices_Data_Snapshot_DID_0x1111_ECUVoltage_ReadData, operation=CSDataServices_Data_Snapshot_DID_0x1111_ECUVoltage.ReadData
        OIT_CSDataServices_Data_Snapshot_DID_0x1117_Sensor_Availability_Flag_Information_ReadData_CSDataServices_Data_Snapshot_DDAA3099C: start-on-event=CSDataServices_Data_Snapshot_DID_0x1117_Sensor_Availability_Flag_Information_ReadData, operation=CSDataServices_Data_Snapshot_DID_0x1117_Sensor_Availability_Flag_Information.ReadData
        OIT_CSDataServices_Data_Snapshot_DID_0xa004_Ego_Acceleration_ReadData_CSDataServices_Data_Snapshot_DID_0xa004_Ego_AcceleA5E32AA8: start-on-event=CSDataServices_Data_Snapshot_DID_0xa004_Ego_Acceleration_ReadData, operation=CSDataServices_Data_Snapshot_DID_0xa004_Ego_Acceleration.ReadData
        OIT_CSDataServices_Data_Snapshot_DID_0x1112_VehicleSpeed_ReadData_CSDataServices_Data_Snapshot_DID_0x1112_VehicleSpeed_ReadData: start-on-event=CSDataServices_Data_Snapshot_DID_0x1112_VehicleSpeed_ReadData, operation=CSDataServices_Data_Snapshot_DID_0x1112_VehicleSpeed.ReadData
        OIT_CSDataServices_Data_Snapshot_DID_0x1116_CombinedSignal_ReadData_CSDataServices_Data_Snapshot_DID_0x1116_CombinedSignA3433445: start-on-event=CSDataServices_Data_Snapshot_DID_0x1116_CombinedSignal_ReadData, operation=CSDataServices_Data_Snapshot_DID_0x1116_CombinedSignal.ReadData
        OIT_ServiceRequestNotification_Confirmation_ServiceRequestNotification_Confirmation: start-on-event=ServiceRequestNotification_Confirmation, operation=ServiceRequestNotification.Confirmation
        OIT_ServiceRequestNotification_Indication_ServiceRequestNotification_Indication: start-on-event=ServiceRequestNotification_Indication, operation=ServiceRequestNotification.Indication
        OIT_RoutineServices_Routine_0x7005_Pin_Position_Unlock_Start_RequestResults_RoutineServices_Routine_0x7005_Pin_Position_DA16A899: start-on-event=RoutineServices_Routine_0x7005_Pin_Position_Unlock_Start_RequestResults, operation=RoutineServices_Routine_0x7005_Pin_Position_Unlock_Start.RequestResults
        OIT_RoutineServices_Routine_0x7005_Pin_Position_Unlock_Start_Start_RoutineServices_Routine_0x7005_Pin_Position_Unlock_St48C89B13: start-on-event=RoutineServices_Routine_0x7005_Pin_Position_Unlock_Start_Start, operation=RoutineServices_Routine_0x7005_Pin_Position_Unlock_Start.Start
        OIT_RoutineServices_Routine_0x0200_CheckProgPreCond_Start_Start_RoutineServices_Routine_0x0200_CheckProgPreCond_Start_Start: start-on-event=RoutineServices_Routine_0x0200_CheckProgPreCond_Start_Start, operation=RoutineServices_Routine_0x0200_CheckProgPreCond_Start.Start
        OIT_RoutineServices_Routine_0x7004_Pin_Position_Lock_Start_RequestResults_RoutineServices_Routine_0x7004_Pin_Position_Lo83125386: start-on-event=RoutineServices_Routine_0x7004_Pin_Position_Lock_Start_RequestResults, operation=RoutineServices_Routine_0x7004_Pin_Position_Lock_Start.RequestResults
        OIT_RoutineServices_Routine_0x7004_Pin_Position_Lock_Start_Start_RoutineServices_Routine_0x7004_Pin_Position_Lock_Start_Start: start-on-event=RoutineServices_Routine_0x7004_Pin_Position_Lock_Start_Start, operation=RoutineServices_Routine_0x7004_Pin_Position_Lock_Start.Start
        OIT_DataServices_Data_0xFDA3_Read_Active_Fault_Table_ConditionCheckRead_DataServices_Data_0xFDA3_Read_Active_Fault_Table8976C99A: start-on-event=DataServices_Data_0xFDA3_Read_Active_Fault_Table_ConditionCheckRead, operation=DataServices_Data_0xFDA3_Read_Active_Fault_Table.ConditionCheckRead
        OIT_DataServices_Data_0xFDA3_Read_Active_Fault_Table_ReadData_DataServices_Data_0xFDA3_Read_Active_Fault_Table_ReadData: start-on-event=DataServices_Data_0xFDA3_Read_Active_Fault_Table_ReadData, operation=DataServices_Data_0xFDA3_Read_Active_Fault_Table.ReadData
        OIT_CSCallbackDTCStatusChange_DTCStatusChanged_CSCallbackDTCStatusChange_DTCStatusChanged: start-on-event=CSCallbackDTCStatusChange_DTCStatusChanged, operation=CSCallbackDTCStatusChange.DTCStatusChanged
        OIT_SecurityAccess_Unlocked_L1_SetSecurityAttemptCounter_SecurityAccess_Unlocked_L1_SetSecurityAttemptCounter: start-on-event=SecurityAccess_Unlocked_L1_SetSecurityAttemptCounter, operation=SecurityAccess_Unlocked_L1.SetSecurityAttemptCounter
        OIT_SecurityAccess_Unlocked_L1_GetSecurityAttemptCounter_SecurityAccess_Unlocked_L1_GetSecurityAttemptCounter: start-on-event=SecurityAccess_Unlocked_L1_GetSecurityAttemptCounter, operation=SecurityAccess_Unlocked_L1.GetSecurityAttemptCounter
        OIT_SecurityAccess_Unlocked_L1_CompareKey_SecurityAccess_Unlocked_L1_CompareKey: start-on-event=SecurityAccess_Unlocked_L1_CompareKey, operation=SecurityAccess_Unlocked_L1.CompareKey
        OIT_SecurityAccess_Unlocked_L1_GetSeed_SecurityAccess_Unlocked_L1_GetSeed: start-on-event=SecurityAccess_Unlocked_L1_GetSeed, operation=SecurityAccess_Unlocked_L1.GetSeed
        OIT_DataServices_Data_0xF01C_Static_Alignment_Result_Parameters_ConditionCheckRead_DataServices_Data_0xF01C_Static_AlignD8019410: start-on-event=DataServices_Data_0xF01C_Static_Alignment_Result_Parameters_ConditionCheckRead, operation=DataServices_Data_0xF01C_Static_Alignment_Result_Parameters.ConditionCheckRead
        OIT_DataServices_Data_0xF01C_Static_Alignment_Result_Parameters_ReadData_DataServices_Data_0xF01C_Static_Alignment_Resul9B0D7DB7: start-on-event=DataServices_Data_0xF01C_Static_Alignment_Result_Parameters_ReadData, operation=DataServices_Data_0xF01C_Static_Alignment_Result_Parameters.ReadData
        OIT_DataServices_Data_0xF011_Static_Alignment_Engineering_Non_Configuration_Parameters_ConditionCheckRead_DataServices_DCF75DAD5: start-on-event=DataServices_Data_0xF011_Static_Alignment_Engineering_Non_Configuration_Parameters_ConditionCheckRead, operation=DataServices_Data_0xF011_Static_Alignment_Engineering_Non_Configuration_Parameters.ConditionCheckRead
        OIT_DataServices_Data_0xF011_Static_Alignment_Engineering_Non_Configuration_Parameters_ReadData_DataServices_Data_0xF0114E070977: start-on-event=DataServices_Data_0xF011_Static_Alignment_Engineering_Non_Configuration_Parameters_ReadData, operation=DataServices_Data_0xF011_Static_Alignment_Engineering_Non_Configuration_Parameters.ReadData
        OIT_RoutineServices_Routine_0x7003_Service_Alignment_Execution_Start_RequestResults_RoutineServices_Routine_0x7003_ServiA1346617: start-on-event=RoutineServices_Routine_0x7003_Service_Alignment_Execution_Start_RequestResults, operation=RoutineServices_Routine_0x7003_Service_Alignment_Execution_Start.RequestResults
        OIT_RoutineServices_Routine_0x7003_Service_Alignment_Execution_Start_Stop_RoutineServices_Routine_0x7003_Service_Alignme44A434DD: start-on-event=RoutineServices_Routine_0x7003_Service_Alignment_Execution_Start_Stop, operation=RoutineServices_Routine_0x7003_Service_Alignment_Execution_Start.Stop
        OIT_RoutineServices_Routine_0x7003_Service_Alignment_Execution_Start_Start_RoutineServices_Routine_0x7003_Service_Alignm60FF78D2: start-on-event=RoutineServices_Routine_0x7003_Service_Alignment_Execution_Start_Start, operation=RoutineServices_Routine_0x7003_Service_Alignment_Execution_Start.Start
        OIT_RoutineServices_Routine_0x7000_Static_Alignment_Execution_Start_RequestResults_RoutineServices_Routine_0x7000_StaticC951749F: start-on-event=RoutineServices_Routine_0x7000_Static_Alignment_Execution_Start_RequestResults, operation=RoutineServices_Routine_0x7000_Static_Alignment_Execution_Start.RequestResults
        OIT_RoutineServices_Routine_0x7000_Static_Alignment_Execution_Start_Stop_RoutineServices_Routine_0x7000_Static_Alignment6EF74555: start-on-event=RoutineServices_Routine_0x7000_Static_Alignment_Execution_Start_Stop, operation=RoutineServices_Routine_0x7000_Static_Alignment_Execution_Start.Stop
        OIT_RoutineServices_Routine_0x7000_Static_Alignment_Execution_Start_Start_RoutineServices_Routine_0x7000_Static_Alignmen1031943F: start-on-event=RoutineServices_Routine_0x7000_Static_Alignment_Execution_Start_Start, operation=RoutineServices_Routine_0x7000_Static_Alignment_Execution_Start.Start
        OIT_DataServices_Data_0xF016_Auto_Alignment_Status_Information_ConditionCheckRead_DataServices_Data_0xF016_Auto_AlignmenC54767F7: start-on-event=DataServices_Data_0xF016_Auto_Alignment_Status_Information_ConditionCheckRead, operation=DataServices_Data_0xF016_Auto_Alignment_Status_Information.ConditionCheckRead
        OIT_DataServices_Data_0xF016_Auto_Alignment_Status_Information_ReadData_DataServices_Data_0xF016_Auto_Alignment_Status_IE39C6DE0: start-on-event=DataServices_Data_0xF016_Auto_Alignment_Status_Information_ReadData, operation=DataServices_Data_0xF016_Auto_Alignment_Status_Information.ReadData
        OIT_DataServices_Data_0xF015_Service_Alignment_Result_Parameters_ConditionCheckRead_DataServices_Data_0xF015_Service_Ali520B7E9E: start-on-event=DataServices_Data_0xF015_Service_Alignment_Result_Parameters_ConditionCheckRead, operation=DataServices_Data_0xF015_Service_Alignment_Result_Parameters.ConditionCheckRead
        OIT_DataServices_Data_0xF015_Service_Alignment_Result_Parameters_ReadData_DataServices_Data_0xF015_Service_Alignment_ResBCFFEA9C: start-on-event=DataServices_Data_0xF015_Service_Alignment_Result_Parameters_ReadData, operation=DataServices_Data_0xF015_Service_Alignment_Result_Parameters.ReadData
        OIT_DataServices_Data_0xF014_Service_Alignment_Engineering_Non_Configuration_Parameters_ConditionCheckRead_DataServices_4EC705AA: start-on-event=DataServices_Data_0xF014_Service_Alignment_Engineering_Non_Configuration_Parameters_ConditionCheckRead, operation=DataServices_Data_0xF014_Service_Alignment_Engineering_Non_Configuration_Parameters.ConditionCheckRead
        OIT_DataServices_Data_0xF014_Service_Alignment_Engineering_Non_Configuration_Parameters_ReadData_DataServices_Data_0xF01E7B35011: start-on-event=DataServices_Data_0xF014_Service_Alignment_Engineering_Non_Configuration_Parameters_ReadData, operation=DataServices_Data_0xF014_Service_Alignment_Engineering_Non_Configuration_Parameters.ReadData
        OIT_DataServices_Data_0xF01B_Manual_Alignment_Execution_WriteData_DataServices_Data_0xF01B_Manual_Alignment_Execution_WriteData: start-on-event=DataServices_Data_0xF01B_Manual_Alignment_Execution_WriteData, operation=DataServices_Data_0xF01B_Manual_Alignment_Execution.WriteData
        OIT_DataServices_Data_0xF01B_Manual_Alignment_Execution_ConditionCheckRead_DataServices_Data_0xF01B_Manual_Alignment_Exe4C1CC3E0: start-on-event=DataServices_Data_0xF01B_Manual_Alignment_Execution_ConditionCheckRead, operation=DataServices_Data_0xF01B_Manual_Alignment_Execution.ConditionCheckRead
        OIT_DataServices_Data_0xF01B_Manual_Alignment_Execution_ReadData_DataServices_Data_0xF01B_Manual_Alignment_Execution_ReadData: start-on-event=DataServices_Data_0xF01B_Manual_Alignment_Execution_ReadData, operation=DataServices_Data_0xF01B_Manual_Alignment_Execution.ReadData
        OIT_DataServices_Data_0xF012_Static_Alignment_Engineering_Read_Parameters_ConditionCheckRead_DataServices_Data_0xF012_St600605D7: start-on-event=DataServices_Data_0xF012_Static_Alignment_Engineering_Read_Parameters_ConditionCheckRead, operation=DataServices_Data_0xF012_Static_Alignment_Engineering_Read_Parameters.ConditionCheckRead
        OIT_DataServices_Data_0xF012_Static_Alignment_Engineering_Read_Parameters_ReadData_DataServices_Data_0xF012_Static_Align735FEBE5: start-on-event=DataServices_Data_0xF012_Static_Alignment_Engineering_Read_Parameters_ReadData, operation=DataServices_Data_0xF012_Static_Alignment_Engineering_Read_Parameters.ReadData
        OIT_DataServices_Data_0xF013_Static_Alignment_Engineering_Write_Configuration_Parameter_WriteData_DataServices_Data_0xF0635C6EC6: start-on-event=DataServices_Data_0xF013_Static_Alignment_Engineering_Write_Configuration_Parameter_WriteData, operation=DataServices_Data_0xF013_Static_Alignment_Engineering_Write_Configuration_Parameter.WriteData
      per-instance-parameters:
        parameter data prototype SWC_UDSHandler_VIN_DefaultValue: sw-calibration-access=READ-WRITE, type=Dt_VIN_T, init-value=constant-reference=C_VIN_T
      88 x runnable:
        DataServices_Data_0xF190_VIN_WriteData
          sync call SC_CS_NvMService_VIN_GetErrorStatus: operation=CS_NvMService_VIN.GetErrorStatus
          sync call SC_CS_NvMService_VIN_WriteBlock: operation=CS_NvMService_VIN.WriteBlock
        DataServices_Data_0xF190_VIN_ConditionCheckRead
        DataServices_Data_0xF190_VIN_ReadData
          sync call SC_CS_NvMService_VIN_ReadBlock: operation=CS_NvMService_VIN.ReadBlock
        RE_SWC_CMP_PRJ_UDSHandler_Main_50ms
          data-receive-point-by-arguments:
            4 x access:
              REC_Rp_PhysicalAdcData_De_PhysicalAdcData: accessed-variable=Rp_PhysicalAdcData.De_PhysicalAdcData
              REC_Rp_OperationModeType_De_OperationMode_System: accessed-variable=Rp_OperationModeType.De_OperationMode_System
              REC_Rp_Platform_FaultTestComplete_Table_De_FaultTestCompleteTable: accessed-variable=Rp_Platform_FaultTestComplete_Table.De_FaultTestCompleteTable
              REC_Rp_SG_VehicleStatus_AL_Vdp_SG_VehicleStatus_AL: accessed-variable=Rp_SG_VehicleStatus_AL.Vdp_SG_VehicleStatus_AL
          data-send-points:
            5 x access:
              SEND_Pp_SW_Version_Info_De_SW_Version_Info: accessed-variable=Pp_SW_Version_Info.De_SW_Version_Info
              SEND_Pp_Calibration_Version_Info_De_Calibration_Version_Info: accessed-variable=Pp_Calibration_Version_Info.De_Calibration_Version_Info
              SEND_Pp_Customer_SW_Version_Info_De_Customer_SW_Version_Info: accessed-variable=Pp_Customer_SW_Version_Info.De_Customer_SW_Version_Info
              SEND_Pp_NvM_lock_Unclock_Status_De_NvM_lock_Unclock_Status: accessed-variable=Pp_NvM_lock_Unclock_Status.De_NvM_lock_Unclock_Status
              SEND_Pp_Security_Access_Ath_Fault_De_Security_Access_Ath_Fault: accessed-variable=Pp_Security_Access_Ath_Fault.De_Security_Access_Ath_Fault
          16 x sync call:
            SC_CS_GetError_Status_Operation: operation=CS_GetError_Status.Operation
            SC_CS_ReadNvM_Value_Operation: operation=CS_ReadNvM_Value.Operation
            SC_CS_NvM_Trigger_Write_NvHandler_Trigger_Write_To_NVM: operation=CS_NvM_Trigger_Write.NvHandler_Trigger_Write_To_NVM
            SC_CS_UDS_Get_Platform_Elapsed_ustime_read: operation=CS_UDS_Get_Platform_Elapsed_ustime.read
            SC_CS_UDS_Get_PlatfromTime_us_read: operation=CS_UDS_Get_PlatfromTime_us.read
            SC_CS_Get_Pinposition_Status_Operation: operation=CS_Get_Pinposition_Status.Operation
            SC_CS_HSE_Security_Compare_key_Operation: operation=CS_HSE_Security_Compare_key.Operation
            SC_CS_HSE_Security_generate_seed_Operation: operation=CS_HSE_Security_generate_seed.Operation
            SC_CS_Control_DTC_Service_Operation: operation=CS_Control_DTC_Service.Operation
            SC_CS_NvMService_AttemptCounter_EraseBlock: operation=CS_NvMService_AttemptCounter.EraseBlock
            SC_CS_NvMService_AttemptCounter_GetErrorStatus: operation=CS_NvMService_AttemptCounter.GetErrorStatus
            SC_CS_NvMService_AttemptCounter_InvalidateNvBlock: operation=CS_NvMService_AttemptCounter.InvalidateNvBlock
            SC_CS_NvMService_AttemptCounter_ReadBlock: operation=CS_NvMService_AttemptCounter.ReadBlock
            SC_CS_NvMService_AttemptCounter_RestoreBlockDefaults: operation=CS_NvMService_AttemptCounter.RestoreBlockDefaults
            SC_CS_NvMService_AttemptCounter_SetRamBlockStatus: operation=CS_NvMService_AttemptCounter.SetRamBlockStatus
            SC_CS_NvMService_AttemptCounter_WriteBlock: operation=CS_NvMService_AttemptCounter.WriteBlock
        DataServices_Data_0x1111_ECUVoltage_ConditionCheckRead
        DataServices_Data_0x1111_ECUVoltage_ReadData
        DataServices_Data_0x1112_VehicleSpeed_ConditionCheckRead
        DataServices_Data_0x1112_VehicleSpeed_ReadData
        DataServices_Data_0x1116_DateandTime_ConditionCheckRead
        DataServices_Data_0x1116_DateandTime_ReadData
        DataServices_Data_0x1117_Sensor_Availability_Flag_ConditionCheckRead
        DataServices_Data_0x1117_Sensor_Availability_Flag_ReadData
        DataServices_Data_0xA000_SerialNumber_ConditionCheckRead
        DataServices_Data_0xA000_SerialNumber_ReadData
        DataServices_Data_0xA001_SoftwareNumber_ConditionCheckRead
        DataServices_Data_0xA001_SoftwareNumber_ReadData
        DataServices_Data_0xA002_Dataset_Part_No_and_Revision_ConditionCheckRead
        DataServices_Data_0xA002_Dataset_Part_No_and_Revision_ReadData
        DataServices_Data_0xA003_SMC_Part_No_and_Revision_ConditionCheckRead
        DataServices_Data_0xA003_SMC_Part_No_and_Revision_ReadData
        DataServices_Data_0xA004_Ego_Acceleration_ConditionCheckRead
        DataServices_Data_0xA004_Ego_Acceleration_ReadData
        DataServices_Data_0xF010_Vehicle_Variant_ConditionCheckRead
        DataServices_Data_0xF010_Vehicle_Variant_ReadData
        DataServices_Data_0xF017_Pin_Position_Status_ConditionCheckRead
        DataServices_Data_0xF017_Pin_Position_Status_ReadData
        DataServices_Data_0xF150_Hardware_Version_number_ConditionCheckRead
        DataServices_Data_0xF150_Hardware_Version_number_ReadData
        DataServices_Data_0xF15A_Software_Fingerprint_WriteData
        DataServices_Data_0xF15A_Software_Fingerprint_ConditionCheckRead
        DataServices_Data_0xF15A_Software_Fingerprint_ReadData
        DataServices_Data_0xF16A_Boot_App_Identification_ConditionCheckRead
        DataServices_Data_0xF16A_Boot_App_Identification_ReadData
        DataServices_Data_0xF180_BootloaderNumber_ConditionCheckRead
        DataServices_Data_0xF180_BootloaderNumber_ReadData
        DataServices_Data_0xF186_ActiveDiagnosticSessionDataIdentifier_ConditionCheckRead
        DataServices_Data_0xF186_ActiveDiagnosticSessionDataIdentifier_ReadData
          sync call SC_DCMServices_GetSesCtrlType: operation=DCMServices.GetSesCtrlType
        DataServices_Data_0xF189_Base_Software_Version_number_ConditionCheckRead
        DataServices_Data_0xF189_Base_Software_Version_number_ReadData
        DataServices_Data_0xF18B_ECUBuildDate_ConditionCheckRead
        DataServices_Data_0xF18B_ECUBuildDate_ReadData
        DataServices_Data_0xF191_HardwareNumber_ConditionCheckRead
        DataServices_Data_0xF191_HardwareNumber_ReadData
        DataServices_Data_0xF19D_CANDBMatrixVer_ConditionCheckRead
        DataServices_Data_0xF19D_CANDBMatrixVer_ReadData
        DataServices_Data_0xF19E_PCAN_DBC_Version_ConditionCheckRead
        DataServices_Data_0xF19E_PCAN_DBC_Version_ReadData
        CSDataServices_Data_Snapshot_DID_0x1111_ECUVoltage_ReadData
        CSDataServices_Data_Snapshot_DID_0x1117_Sensor_Availability_Flag_Information_ReadData
        CSDataServices_Data_Snapshot_DID_0xa004_Ego_Acceleration_ReadData
        CSDataServices_Data_Snapshot_DID_0x1112_VehicleSpeed_ReadData
        CSDataServices_Data_Snapshot_DID_0x1116_CombinedSignal_ReadData
        ServiceRequestNotification_Confirmation
        ServiceRequestNotification_Indication
        RoutineServices_Routine_0x7005_Pin_Position_Unlock_Start_RequestResults
        RoutineServices_Routine_0x7005_Pin_Position_Unlock_Start_Start
        RoutineServices_Routine_0x0200_CheckProgPreCond_Start_Start
        RoutineServices_Routine_0x7004_Pin_Position_Lock_Start_RequestResults
        RoutineServices_Routine_0x7004_Pin_Position_Lock_Start_Start
        DataServices_Data_0xFDA3_Read_Active_Fault_Table_ConditionCheckRead
        DataServices_Data_0xFDA3_Read_Active_Fault_Table_ReadData
        CSCallbackDTCStatusChange_DTCStatusChanged
        SecurityAccess_Unlocked_L1_SetSecurityAttemptCounter
        SecurityAccess_Unlocked_L1_GetSecurityAttemptCounter
        SecurityAccess_Unlocked_L1_CompareKey
        SecurityAccess_Unlocked_L1_GetSeed
        DataServices_Data_0xF01C_Static_Alignment_Result_Parameters_ConditionCheckRead
        DataServices_Data_0xF01C_Static_Alignment_Result_Parameters_ReadData
        DataServices_Data_0xF011_Static_Alignment_Engineering_Non_Configuration_Parameters_ConditionCheckRead
        DataServices_Data_0xF011_Static_Alignment_Engineering_Non_Configuration_Parameters_ReadData
          data-receive-point-by-arguments:
            access REC_Rp_StaticAlignment_NonConfig_Param_De_DID_StaticAlignment_NonConfig_Param_T: accessed-variable=Rp_StaticAlignment_NonConfig_Param.De_DID_StaticAlignment_NonConfig_Param_T
        RoutineServices_Routine_0x7003_Service_Alignment_Execution_Start_RequestResults
        RoutineServices_Routine_0x7003_Service_Alignment_Execution_Start_Stop
        RoutineServices_Routine_0x7003_Service_Alignment_Execution_Start_Start
        RoutineServices_Routine_0x7000_Static_Alignment_Execution_Start_RequestResults
        RoutineServices_Routine_0x7000_Static_Alignment_Execution_Start_Stop
        RoutineServices_Routine_0x7000_Static_Alignment_Execution_Start_Start
        DataServices_Data_0xF016_Auto_Alignment_Status_Information_ConditionCheckRead
        DataServices_Data_0xF016_Auto_Alignment_Status_Information_ReadData
          data-receive-point-by-arguments:
            access REC_Rp_Auto_Alignment_Status_Information_De_Auto_Alignment_Status_Information: accessed-variable=Rp_Auto_Alignment_Status_Information.De_Auto_Alignment_Status_Information
        DataServices_Data_0xF015_Service_Alignment_Result_Parameters_ConditionCheckRead
        DataServices_Data_0xF015_Service_Alignment_Result_Parameters_ReadData
          data-receive-point-by-arguments:
            access REC_Rp_Service_Alignment_Result_Parameters_De_Service_Alignment_Result_Parameters: accessed-variable=Rp_Service_Alignment_Result_Parameters.De_Service_Alignment_Result_Parameters
        DataServices_Data_0xF014_Service_Alignment_Engineering_Non_Configuration_Parameters_ConditionCheckRead
        DataServices_Data_0xF014_Service_Alignment_Engineering_Non_Configuration_Parameters_ReadData
          data-receive-point-by-arguments:
            access REC_Rp_Service_Alignment_Engineering_Non_Configuration_Parameters_De_Service_Alignment_Engineering_Non_Configuration_Parameters: accessed-variable=Rp_Service_Alignment_Engineering_Non_Configuration_Parameters.De_Service_Alignment_Engineering_Non_Configuration_Parameters
        DataServices_Data_0xF01B_Manual_Alignment_Execution_WriteData
          data-send-points:
            access SEND_Pp_Manual_Alignment_Execution_Data_From_UDS_CRC_De_Manual_Alignment_Execution_Data_CRC: accessed-variable=Pp_Manual_Alignment_Execution_Data_From_UDS_CRC.De_Manual_Alignment_Execution_Data_CRC
        DataServices_Data_0xF01B_Manual_Alignment_Execution_ConditionCheckRead
        DataServices_Data_0xF01B_Manual_Alignment_Execution_ReadData
          data-receive-point-by-arguments:
            access REC_Rp_Manual_Alignment_Execution_Read_From_Alignment_Data_CRC_De_Manual_Alignment_Execution_Data_CRC: accessed-variable=Rp_Manual_Alignment_Execution_Read_From_Alignment_Data_CRC.De_Manual_Alignment_Execution_Data_CRC
        DataServices_Data_0xF012_Static_Alignment_Engineering_Read_Parameters_ConditionCheckRead
        DataServices_Data_0xF012_Static_Alignment_Engineering_Read_Parameters_ReadData
          data-receive-point-by-arguments:
            access REC_Rp_Static_Alignment_Engineering_Parameters_De_Static_Alignment_Engineering_Parameters: accessed-variable=Rp_Static_Alignment_Engineering_Parameters.De_Static_Alignment_Engineering_Parameters
        DataServices_Data_0xF013_Static_Alignment_Engineering_Write_Configuration_Parameter_WriteData
          data-send-points:
            access SEND_Pp_Static_Alignment_Engineering_Write_Configuration_Parameters_CRC_De_Static_Alignment_Engineering_Write_Configurat6D9EDFB8: accessed-variable=Pp_Static_Alignment_Engineering_Write_Configuration_Parameters_CRC.De_Static_Alignment_Engineering_Write_Configuration_Parameters_CRC
      swc service dependency SWC_UDSHandler_VIN: category=SERVICE
        assigned-datas:
          role=defaultValue, used-parameter-element=SWC_UDSHandler_VIN_DefaultValue
          role=ramBlock, used-data-element=SWC_UDS_VIN
        assigned-ports:
          NvMService_AC3_SRBS_Defs
          NvMService_AC3_SRBS_Defs
          port-prototype=CS_NvMService_VIN, role=NvMService_AC3_SRBS_Defs
        service-needs:
          nv block needs SWC_UDSHandler_VIN: n-rom-blocks=1, ram-block-status-control=API, reliability=ERROR-DETECTION, restore-at-start=true, store-at-shutdown=true, writing-priority=LOW
      swc service dependency SWC_UDSHandler_Attemptcounter: category=SERVICE, assigned-ports=role-based-port-assignment={port-prototype=CS_NvMService_AttemptCounter, role=NvMService_AC3_SRBS_Defs}
        assigned-datas:
          role=ramBlock, used-data-element=SWC_UDS_AttemptCounter
          role=defaultValue, used-parameter-element=SWC_UDSHandler_Attemptcounter_DefaultValue
        service-needs:
          nv block needs SWC_UDSHandler_Attemptcounter: n-rom-blocks=1, ram-block-status-control=API, reliability=ERROR-DETECTION, restore-at-start=true, store-at-shutdown=true, writing-priority=LOW
      shared-parameters:
        parameter data prototype SWC_UDSHandler_Attemptcounter_DefaultValue: sw-calibration-access=READ-WRITE, type=AttempCounter_Type, init-value=fields=[AttemptCounter1:0, AttemptCounter2:0]
  swc implementation SWC_CMP_PRJ_UDSHandler_Implementation: behavior=SWC_CMP_PRJ_UDSHandler_InternalBehavior
